AUTOSAR XML (schema 4.0)
package /AppComponents
  sender receiver interface TempRequest_I
    data TargetTemp
  sender receiver interface BlowerCmd_I
    data BlowerLevel
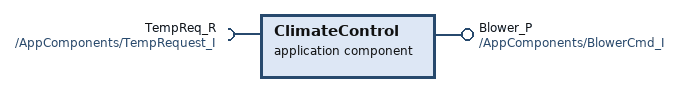
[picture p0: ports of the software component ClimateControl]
  application sw component type ClimateControl
    require port TempReq_R: required-interface=/AppComponents/TempRequest_I
    provide port Blower_P: provided-interface=/AppComponents/BlowerCmd_I
